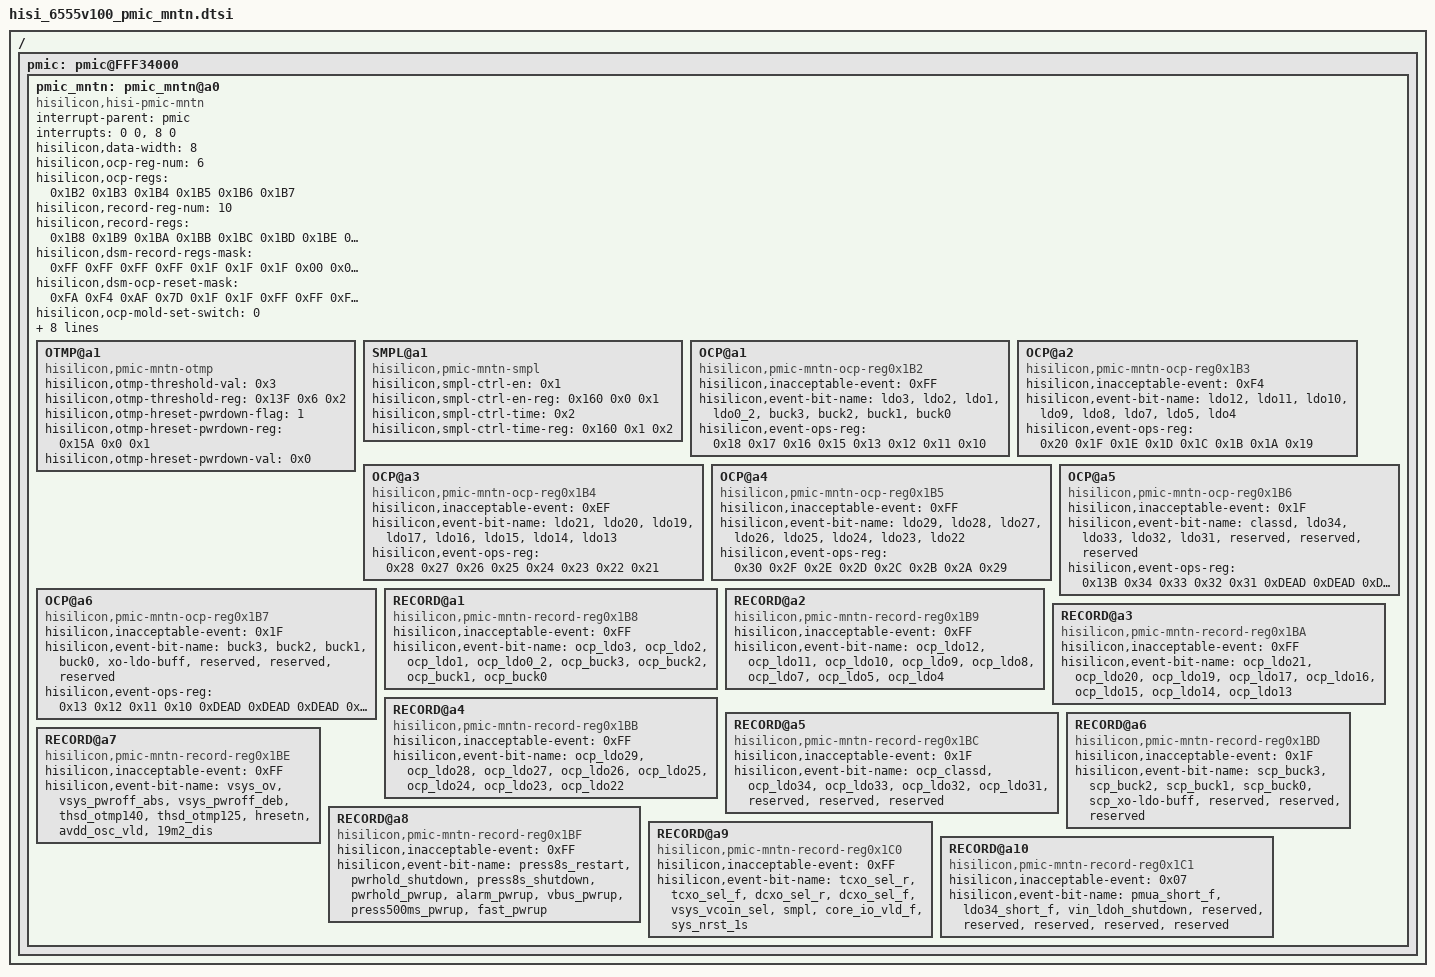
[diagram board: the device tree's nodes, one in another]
/******************************************************************************

                  版权所有 (C), 2001-2011, 华为技术有限公司

 ******************************************************************************

  This is an AUTO GENERATED file ! DON'T MODIFY MANUAL!
  文 件 名   : %(filename)s
  生成日期   : %(year)d年%(month)d月%(day)d日

******************************************************************************/

/ {
    pmic: pmic@FFF34000 {
		pmic_mntn: pmic_mntn@a0 {
					compatible = "hisilicon,hisi-pmic-mntn";
					interrupt-parent = <&pmic>;
					interrupts = <0 0>, <8 0>;
					interrupt-names = "otmp", "ocp";
					hisilicon,data-width = <8>;
					hisilicon,ocp-reg-num = <6>;
					hisilicon,ocp-regs = <0x1B2 0x1B3 0x1B4 0x1B5 0x1B6 0x1B7>;
					hisilicon,record-reg-num = <10>;
					hisilicon,record-regs = <0x1B8 0x1B9 0x1BA 0x1BB 0x1BC 0x1BD 0x1BE 0x1BF 0x1C0 0x1C1>;
					/* this para is up to PDU, for different products may have different values */
					hisilicon,dsm-record-regs-mask = <0xFF 0xFF 0xFF 0xFF 0x1F 0x1F 0x1F 0x00 0x00 0x00>;
					hisilicon,dsm-ocp-reset-mask = <0xFA 0xF4 0xAF 0x7D 0x1F 0x1F 0xFF 0xFF 0xFF 0x07>;
					hisilicon,ocp-mold-set-switch = <0>;
					hisilicon,ocp-ctrl-num = <8>;
					hisilicon,ocp-ctrl-regs = <0x101 0x102 0x103 0x104 0x105 0x106 0x107 0x108>;
					hisilicon,ocp-ctrl-value = <0xF3 0x00 0xC0 0x00 0x00 0x00 0x3C 0x00>;
					hisilicon,pmu-record-reg-num = <5>;
					hisilicon,pmu-record-regs = <0x15B 0x03A 0x03B 0x03C 0x03D>;

					OTMP@a1 {
						compatible = "hisilicon,pmic-mntn-otmp";
						/*otmp threshold value: 0x0->95, 0x1->105, 0x2->115, 0x3->125*/
						hisilicon,otmp-threshold-val = <0x3>;
						hisilicon,otmp-threshold-reg = <0x13F 0x6 0x2>;
						/*chip bug:do cold reset if pwrdown-flag == 1 && pwrdown-val == 0x0;do hot reset if pwrdown-flag == 0*/
						hisilicon,otmp-hreset-pwrdown-flag = <1>;
						hisilicon,otmp-hreset-pwrdown-reg = <0x15A 0x0 0x1>;
						hisilicon,otmp-hreset-pwrdown-val = <0x0>;
					};

					SMPL@a1 {
						compatible = "hisilicon,pmic-mntn-smpl";
						hisilicon,smpl-ctrl-en = <0x1>;
						hisilicon,smpl-ctrl-en-reg = <0x160 0x0 0x1>;
						/*smpl ctrl time: 0x0->0.5s, 0x1->1.0s, 0x2->1.5s, 0x3->2.0s*/
						hisilicon,smpl-ctrl-time = <0x2>;
						hisilicon,smpl-ctrl-time-reg = <0x160 0x1 0x2>;
					};

					OCP@a1 {
						compatible = "hisilicon,pmic-mntn-ocp-reg0x1B2";
						hisilicon,inacceptable-event = <0xFF>;
						hisilicon,event-bit-name = "ldo3","ldo2","ldo1","ldo0_2","buck3","buck2","buck1","buck0";
						hisilicon,event-ops-reg = <0x18 0x17 0x16 0x15 0x13 0x12 0x11 0x10>;
					};

					OCP@a2 {
						compatible = "hisilicon,pmic-mntn-ocp-reg0x1B3";
						hisilicon,inacceptable-event = <0xF4>;
						hisilicon,event-bit-name = "ldo12","ldo11","ldo10","ldo9","ldo8","ldo7","ldo5","ldo4";
						hisilicon,event-ops-reg = <0x20 0x1F 0x1E 0x1D 0x1C 0x1B 0x1A 0x19>;
					};

					OCP@a3 {
						compatible = "hisilicon,pmic-mntn-ocp-reg0x1B4";
						hisilicon,inacceptable-event = <0xEF>;
						hisilicon,event-bit-name = "ldo21","ldo20","ldo19","ldo17","ldo16","ldo15","ldo14","ldo13";
						hisilicon,event-ops-reg = <0x28 0x27 0x26 0x25 0x24 0x23 0x22 0x21>;
					};

					OCP@a4 {
						compatible = "hisilicon,pmic-mntn-ocp-reg0x1B5";
						hisilicon,inacceptable-event = <0xFF>;
						hisilicon,event-bit-name = "ldo29","ldo28","ldo27","ldo26","ldo25","ldo24","ldo23","ldo22";
						hisilicon,event-ops-reg = <0x30 0x2F 0x2E 0x2D 0x2C 0x2B 0x2A 0x29>;
					};

					OCP@a5 {
						compatible = "hisilicon,pmic-mntn-ocp-reg0x1B6";
						hisilicon,inacceptable-event = <0x1F>;
						hisilicon,event-bit-name = "classd","ldo34","ldo33","ldo32","ldo31","reserved","reserved","reserved";
						hisilicon,event-ops-reg = <0x13B 0x34 0x33 0x32 0x31 0xDEAD 0xDEAD 0xDEAD>;
					};

					OCP@a6 {
						compatible = "hisilicon,pmic-mntn-ocp-reg0x1B7";
						hisilicon,inacceptable-event = <0x1F>;
						hisilicon,event-bit-name = "buck3","buck2","buck1","buck0","xo-ldo-buff","reserved","reserved","reserved";
						hisilicon,event-ops-reg = <0x13 0x12 0x11 0x10 0xDEAD 0xDEAD 0xDEAD 0xDEAD>;
					};

					RECORD@a1 {
						compatible = "hisilicon,pmic-mntn-record-reg0x1B8";
						hisilicon,inacceptable-event = <0xFF>;
						hisilicon,event-bit-name = "ocp_ldo3","ocp_ldo2","ocp_ldo1","ocp_ldo0_2","ocp_buck3","ocp_buck2","ocp_buck1","ocp_buck0";
					};

					RECORD@a2 {
						compatible = "hisilicon,pmic-mntn-record-reg0x1B9";
						hisilicon,inacceptable-event = <0xFF>;
						hisilicon,event-bit-name = "ocp_ldo12","ocp_ldo11","ocp_ldo10","ocp_ldo9","ocp_ldo8","ocp_ldo7","ocp_ldo5","ocp_ldo4";
					};

					RECORD@a3 {
						compatible = "hisilicon,pmic-mntn-record-reg0x1BA";
						hisilicon,inacceptable-event = <0xFF>;
						hisilicon,event-bit-name = "ocp_ldo21","ocp_ldo20","ocp_ldo19","ocp_ldo17","ocp_ldo16","ocp_ldo15","ocp_ldo14","ocp_ldo13";
					};

					RECORD@a4 {
						compatible = "hisilicon,pmic-mntn-record-reg0x1BB";
						hisilicon,inacceptable-event = <0xFF>;
						hisilicon,event-bit-name = "ocp_ldo29","ocp_ldo28","ocp_ldo27","ocp_ldo26","ocp_ldo25","ocp_ldo24","ocp_ldo23","ocp_ldo22";
					};

					RECORD@a5 {
						compatible = "hisilicon,pmic-mntn-record-reg0x1BC";
						hisilicon,inacceptable-event = <0x1F>;
						hisilicon,event-bit-name = "ocp_classd","ocp_ldo34","ocp_ldo33","ocp_ldo32","ocp_ldo31","reserved","reserved","reserved";
					};

					RECORD@a6 {
						compatible = "hisilicon,pmic-mntn-record-reg0x1BD";
						hisilicon,inacceptable-event = <0x1F>;
						hisilicon,event-bit-name = "scp_buck3","scp_buck2","scp_buck1","scp_buck0","scp_xo-ldo-buff","reserved","reserved","reserved";
					};

					RECORD@a7 {
						compatible = "hisilicon,pmic-mntn-record-reg0x1BE";
						hisilicon,inacceptable-event = <0xFF>;
						hisilicon,event-bit-name = "vsys_ov","vsys_pwroff_abs","vsys_pwroff_deb","thsd_otmp140","thsd_otmp125","hresetn","avdd_osc_vld","19m2_dis";
					};

					RECORD@a8 {
						compatible = "hisilicon,pmic-mntn-record-reg0x1BF";
						hisilicon,inacceptable-event = <0xFF>;
						hisilicon,event-bit-name = "press8s_restart","pwrhold_shutdown","press8s_shutdown","pwrhold_pwrup","alarm_pwrup","vbus_pwrup","press500ms_pwrup","fast_pwrup";
					};

					RECORD@a9 {
						compatible = "hisilicon,pmic-mntn-record-reg0x1C0";
						hisilicon,inacceptable-event = <0xFF>;
						hisilicon,event-bit-name = "tcxo_sel_r","tcxo_sel_f","dcxo_sel_r","dcxo_sel_f","vsys_vcoin_sel","smpl","core_io_vld_f","sys_nrst_1s";
					};

					RECORD@a10 {
						compatible = "hisilicon,pmic-mntn-record-reg0x1C1";
						hisilicon,inacceptable-event = <0x07>;
						hisilicon,event-bit-name = "pmua_short_f","ldo34_short_f","vin_ldoh_shutdown","reserved","reserved","reserved","reserved","reserved";
					};
		};
	};
};
